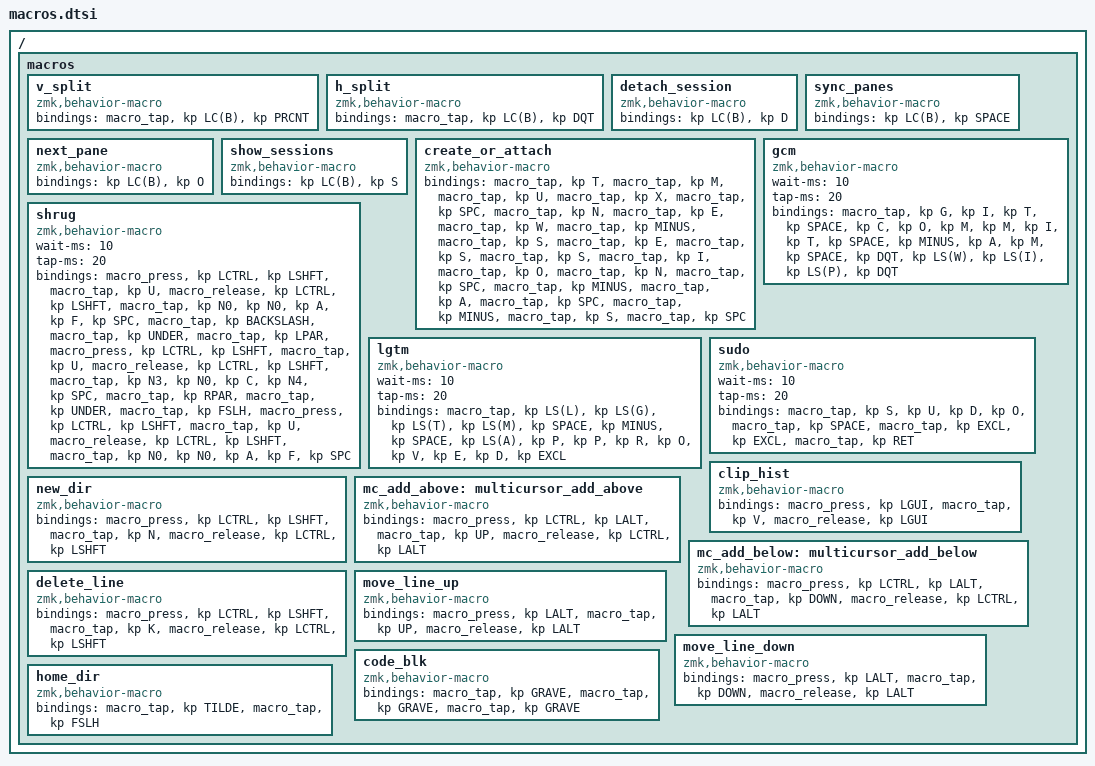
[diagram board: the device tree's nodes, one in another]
/ {
    macros {
        v_split: v_split {
            compatible = "zmk,behavior-macro";
            #binding-cells = <0>;
            bindings = <&macro_tap>, <&kp LC(B) &kp PRCNT>;
        };

        h_split: h_split {
            compatible = "zmk,behavior-macro";
            #binding-cells = <0>;
            bindings = <&macro_tap>, <&kp LC(B) &kp DQT>;
        };

        detach_session: detach_session {
            compatible = "zmk,behavior-macro";
            #binding-cells = <0>;
            bindings = <&kp LC(B) &kp D>;
        };

        sync_panes: sync_panes {
            compatible = "zmk,behavior-macro";
            #binding-cells = <0>;
            bindings = <&kp LC(B) &kp SPACE>;
        };

        next_pane: next_pane {
            compatible = "zmk,behavior-macro";
            #binding-cells = <0>;
            bindings = <&kp LC(B) &kp O>;
        };

        show_sessions: show_sessions {
            compatible = "zmk,behavior-macro";
            #binding-cells = <0>;
            bindings = <&kp LC(B) &kp S>;
        };

        create_or_attach: create_or_attach {
            compatible = "zmk,behavior-macro";
            #binding-cells = <0>;
            bindings =
                <&macro_tap>,
                <&kp T>,
                <&macro_tap>,
                <&kp M>,
                <&macro_tap>,
                <&kp U>,
                <&macro_tap>,
                <&kp X>,
                <&macro_tap>,
                <&kp SPC>,
                <&macro_tap>,
                <&kp N>,
                <&macro_tap>,
                <&kp E>,
                <&macro_tap>,
                <&kp W>,
                <&macro_tap>,
                <&kp MINUS>,
                <&macro_tap>,
                <&kp S>,
                <&macro_tap>,
                <&kp E>,
                <&macro_tap>,
                <&kp S>,
                <&macro_tap>,
                <&kp S>,
                <&macro_tap>,
                <&kp I>,
                <&macro_tap>,
                <&kp O>,
                <&macro_tap>,
                <&kp N>,
                <&macro_tap>,
                <&kp SPC>,
                <&macro_tap>,
                <&kp MINUS>,
                <&macro_tap>,
                <&kp A>,
                <&macro_tap>,
                <&kp SPC>,
                <&macro_tap>,
                <&kp MINUS>,
                <&macro_tap>,
                <&kp S>,
                <&macro_tap>,
                <&kp SPC>;
        };

        shrug: shrug {
            compatible = "zmk,behavior-macro";
            #binding-cells = <0>;
            wait-ms = <10>;
            tap-ms = <20>;
            bindings =
                <&macro_press>,
                <&kp LCTRL &kp LSHFT>,
                <&macro_tap>,
                <&kp U>,
                <&macro_release>,
                <&kp LCTRL &kp LSHFT>,
                <&macro_tap>,
                <&kp N0 &kp N0 &kp A &kp F &kp SPC>,
                <&macro_tap>,
                <&kp BACKSLASH>,
                <&macro_tap>,
                <&kp UNDER>,
                <&macro_tap>,
                <&kp LPAR>,
                <&macro_press>,
                <&kp LCTRL &kp LSHFT>,
                <&macro_tap>,
                <&kp U>,
                <&macro_release>,
                <&kp LCTRL &kp LSHFT>,
                <&macro_tap>,
                <&kp N3 &kp N0 &kp C &kp N4 &kp SPC>,
                <&macro_tap>,
                <&kp RPAR>,
                <&macro_tap>,
                <&kp UNDER>,
                <&macro_tap>,
                <&kp FSLH>,
                <&macro_press>,
                <&kp LCTRL &kp LSHFT>,
                <&macro_tap>,
                <&kp U>,
                <&macro_release>,
                <&kp LCTRL &kp LSHFT>,
                <&macro_tap>,
                <&kp N0 &kp N0 &kp A &kp F &kp SPC>;
        };

        gcm: gcm {
            compatible = "zmk,behavior-macro";
            #binding-cells = <0>;
            wait-ms = <10>;
            tap-ms = <20>;
            bindings =
                <&macro_tap>,
                <&kp G &kp I &kp T &kp SPACE &kp C &kp O &kp M &kp M &kp I &kp T &kp SPACE &kp MINUS &kp A &kp M &kp SPACE &kp DQT &kp LS(W) &kp LS(I) &kp LS(P) &kp DQT>;
        };

        lgtm: lgtm {
            compatible = "zmk,behavior-macro";
            #binding-cells = <0>;
            wait-ms = <10>;
            tap-ms = <20>;
            bindings =
                <&macro_tap>,
                <&kp LS(L) &kp LS(G) &kp LS(T) &kp LS(M) &kp SPACE &kp MINUS &kp SPACE &kp LS(A) &kp P &kp P &kp R &kp O &kp V &kp E &kp D &kp EXCL>;
        };

        sudo: sudo {
            compatible = "zmk,behavior-macro";
            #binding-cells = <0>;
            wait-ms = <10>;
            tap-ms = <20>;
            bindings =
                <&macro_tap>,
                <&kp S &kp U &kp D &kp O>,
                <&macro_tap>,
                <&kp SPACE>,
                <&macro_tap>,
                <&kp EXCL &kp EXCL>,
                <&macro_tap>,
                <&kp RET>;
        };

        clip_hist: clip_hist {
            compatible = "zmk,behavior-macro";
            #binding-cells = <0>;
            bindings =
                <&macro_press>,
                <&kp LGUI>,
                <&macro_tap>,
                <&kp V>,
                <&macro_release>,
                <&kp LGUI>;
        };

        new_dir: new_dir {
            compatible = "zmk,behavior-macro";
            #binding-cells = <0>;
            bindings =
                <&macro_press>,
                <&kp LCTRL &kp LSHFT>,
                <&macro_tap>,
                <&kp N>,
                <&macro_release>,
                <&kp LCTRL &kp LSHFT>;
        };

        mc_add_above: multicursor_add_above {
            compatible = "zmk,behavior-macro";
            #binding-cells = <0>;
            bindings =
                <&macro_press>,
                <&kp LCTRL &kp LALT>,
                <&macro_tap>,
                <&kp UP>,
                <&macro_release>,
                <&kp LCTRL &kp LALT>;
        };

        mc_add_below: multicursor_add_below {
            compatible = "zmk,behavior-macro";
            #binding-cells = <0>;
            bindings =
                <&macro_press>,
                <&kp LCTRL &kp LALT>,
                <&macro_tap>,
                <&kp DOWN>,
                <&macro_release>,
                <&kp LCTRL &kp LALT>;
        };

        delete_line: delete_line {
            compatible = "zmk,behavior-macro";
            #binding-cells = <0>;
            bindings =
                <&macro_press>,
                <&kp LCTRL &kp LSHFT>,
                <&macro_tap>,
                <&kp K>,
                <&macro_release>,
                <&kp LCTRL &kp LSHFT>;
        };

        move_line_up: move_line_up {
            compatible = "zmk,behavior-macro";
            #binding-cells = <0>;
            bindings =
                <&macro_press>,
                <&kp LALT>,
                <&macro_tap>,
                <&kp UP>,
                <&macro_release>,
                <&kp LALT>;
        };

        move_line_down: move_line_down {
            compatible = "zmk,behavior-macro";
            #binding-cells = <0>;
            bindings =
                <&macro_press>,
                <&kp LALT>,
                <&macro_tap>,
                <&kp DOWN>,
                <&macro_release>,
                <&kp LALT>;
        };

        code_blk: code_blk {
            compatible = "zmk,behavior-macro";
            #binding-cells = <0>;
            bindings =
                <&macro_tap>,
                <&kp GRAVE>,
                <&macro_tap>,
                <&kp GRAVE>,
                <&macro_tap>,
                <&kp GRAVE>;
        };

        home_dir: home_dir {
            compatible = "zmk,behavior-macro";
            #binding-cells = <0>;
            bindings = <&macro_tap>, <&kp TILDE>, <&macro_tap>, <&kp FSLH>;
        };
    };
};
